VERSION ""

NS_ :

BS_:

BU_: XXX

BO_ 85 CID_JIHOEY: 8 XXX
 SG_ sig_gnukuz : 40|1@1+ (1,0) [0|1] "" XXX
 SG_ sig_xpkfer : 56|8@1+ (1,0) [0|255] "" XXX

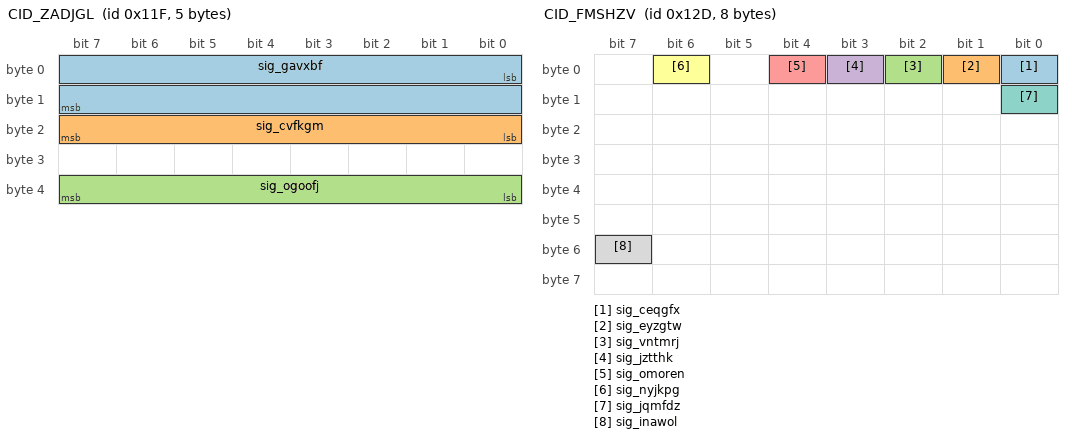
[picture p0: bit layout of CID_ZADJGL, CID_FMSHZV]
BO_ 287 CID_ZADJGL: 5 XXX
 SG_ sig_gavxbf : 0|16@1- (0.1,0) [-450|450] "" XXX
 SG_ sig_cvfkgm : 16|8@1+ (4,0) [0|1020] "" XXX
 SG_ sig_ogoofj : 32|8@1+ (1,0) [0|255] "" XXX

BO_ 289 CID_RFFWJK: 8 XXX
 SG_ sig_duxhzy : 0|12@1+ (1,0) [0|255] "" XXX

BO_ 301 CID_FMSHZV: 8 XXX
 SG_ sig_ceqgfx : 0|1@0+ (1,0) [0|1] "" XXX
 SG_ sig_eyzgtw : 1|1@0+ (1,0) [0|1] "" XXX
 SG_ sig_vntmrj : 2|1@0+ (1,0) [0|1] "" XXX
 SG_ sig_jztthk : 3|1@0+ (1,0) [0|1] "" XXX
 SG_ sig_omoren : 4|1@0+ (1,0) [0|1] "" XXX
 SG_ sig_nyjkpg : 6|1@0+ (1,0) [0|1] "" XXX
 SG_ sig_jqmfdz : 8|1@0+ (1,0) [0|1] "" XXX
 SG_ sig_inawol : 55|1@0+ (1,0) [0|1] "" XXX

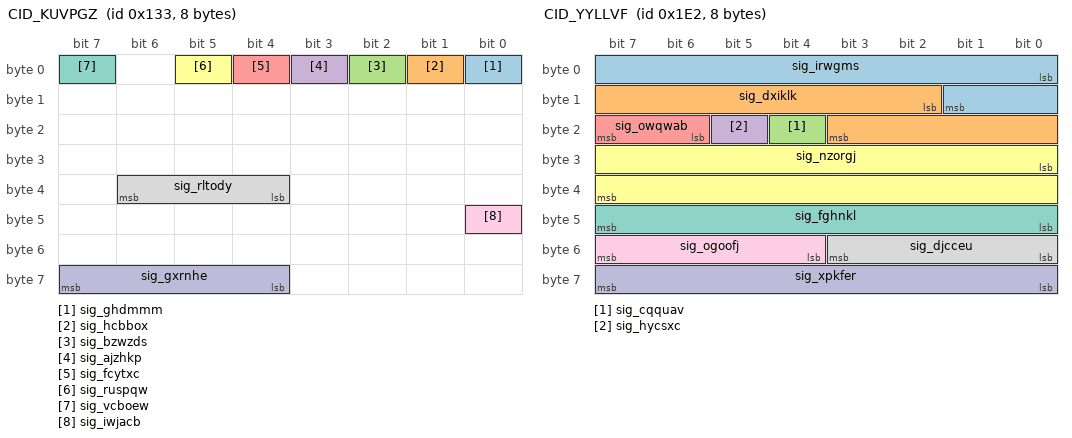
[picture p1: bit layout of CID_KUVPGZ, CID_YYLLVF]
BO_ 307 CID_KUVPGZ: 8 XXX
 SG_ sig_ghdmmm : 0|1@0+ (1,0) [0|1] "" XXX
 SG_ sig_hcbbox : 1|1@1+ (1,0) [0|1] "" XXX
 SG_ sig_bzwzds : 2|1@1+ (1,0) [0|1] "" XXX
 SG_ sig_ajzhkp : 3|1@1+ (1,0) [0|1] "" XXX
 SG_ sig_fcytxc : 4|1@0+ (1,0) [0|1] "" XXX
 SG_ sig_ruspqw : 5|1@0+ (1,0) [0|1] "" XXX
 SG_ sig_vcboew : 7|1@0+ (1,0) [0|1] "" XXX
 SG_ sig_rltody : 36|3@1+ (1,0) [0|7] "" XXX
 SG_ sig_iwjacb : 40|1@0+ (1,0) [0|1] "" XXX
 SG_ sig_gxrnhe : 63|4@0+ (1,0) [0|15] "" XXX

BO_ 482 CID_YYLLVF: 8 XXX
 SG_ sig_irwgms : 0|10@1- (0.01,0) [0|5] "" XXX
 SG_ sig_dxiklk : 10|10@1- (0.01,0) [-5|0] "" XXX
 SG_ sig_cqquav : 20|1@0+ (1,0) [0|1] "" XXX
 SG_ sig_hycsxc : 21|1@0+ (1,0) [0|1] "" XXX
 SG_ sig_owqwab : 22|2@1+ (1,0) [0|1] "" XXX
 SG_ sig_nzorgj : 24|16@1- (0.1,0) [-780|779.9] "" XXX
 SG_ sig_fghnkl : 47|8@0+ (1,0) [0|255] "" XXX
 SG_ sig_djcceu : 48|4@1+ (1,0) [0|15] "" XXX
 SG_ sig_ogoofj : 52|4@1+ (1,0) [0|15] "" XXX
 SG_ sig_xpkfer : 56|8@1+ (1,0) [0|255] "" XXX

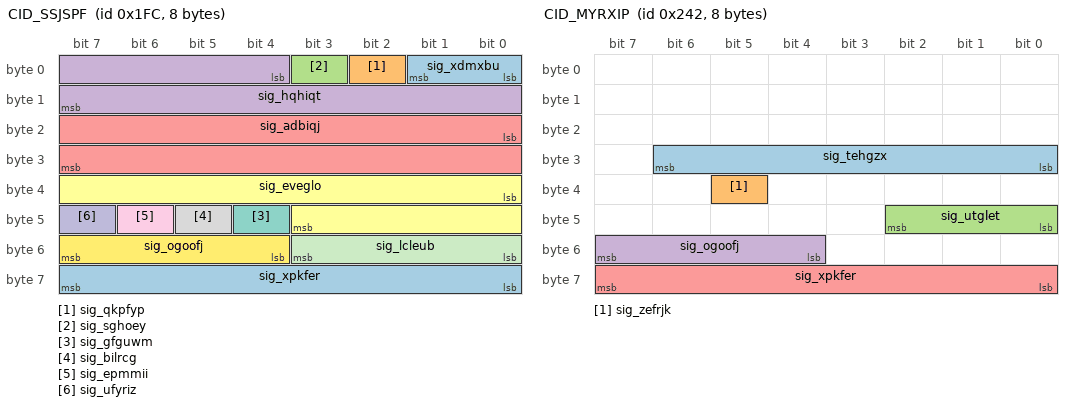
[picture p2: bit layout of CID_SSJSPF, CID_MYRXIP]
BO_ 508 CID_SSJSPF: 8 XXX
 SG_ sig_xdmxbu : 0|2@1+ (1,0) [0|1] "" XXX
 SG_ sig_qkpfyp : 2|1@1+ (1,0) [0|1] "" XXX
 SG_ sig_sghoey : 3|1@0+ (1,0) [0|1] "" XXX
 SG_ sig_hqhiqt : 4|12@1- (1,0) [-2048|2047] "" XXX
 SG_ sig_adbiqj : 16|16@1- (0.1,0) [-780|779.9] "Deg" XXX
 SG_ sig_eveglo : 32|12@1- (1,0) [0|63] "" XXX
 SG_ sig_gfguwm : 44|1@0+ (1,0) [0|1] "" XXX
 SG_ sig_bilrcg : 45|1@1+ (1,0) [0|255] "" XXX
 SG_ sig_epmmii : 46|1@1+ (1,0) [0|1] "" XXX
 SG_ sig_ufyriz : 47|1@0+ (1,0) [0|3] "" XXX
 SG_ sig_lcleub : 48|4@1+ (1,0) [0|15] "" XXX
 SG_ sig_ogoofj : 52|4@1+ (1,0) [0|15] "" XXX
 SG_ sig_xpkfer : 56|8@1+ (1,0) [0|255] "" XXX

BO_ 578 CID_MYRXIP: 8 XXX
 SG_ sig_tehgzx : 30|7@0+ (1,0) [0|127] "" XXX
 SG_ sig_zefrjk : 37|1@0+ (1,0) [0|1] "" XXX
 SG_ sig_utglet : 40|3@1+ (1,0) [0|7] "" XXX
 SG_ sig_ogoofj : 55|4@0+ (1,0) [0|15] "" XXX
 SG_ sig_xpkfer : 56|8@1+ (1,0) [0|255] "" XXX

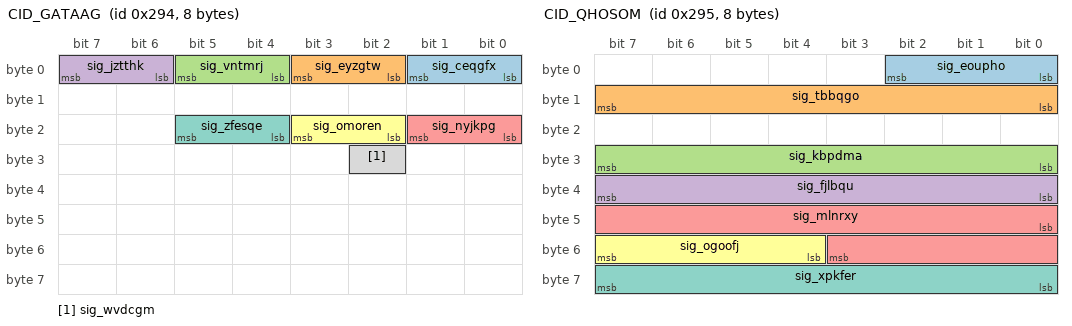
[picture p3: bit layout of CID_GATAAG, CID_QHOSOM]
BO_ 660 CID_GATAAG: 8 XXX
 SG_ sig_ceqgfx : 1|2@0+ (1,0) [0|3] "" XXX
 SG_ sig_eyzgtw : 3|2@0+ (1,0) [0|3] "" XXX
 SG_ sig_vntmrj : 5|2@0+ (1,0) [0|3] "" XXX
 SG_ sig_jztthk : 7|2@0+ (1,0) [0|3] "" XXX
 SG_ sig_nyjkpg : 17|2@0+ (1,0) [0|3] "" XXX
 SG_ sig_omoren : 19|2@0+ (1,0) [0|3] "" XXX
 SG_ sig_zfesqe : 21|2@0+ (1,0) [0|3] "" XXX
 SG_ sig_wvdcgm : 26|1@0+ (1,0) [0|1] "" XXX

BO_ 661 CID_QHOSOM: 8 XXX
 SG_ sig_eoupho : 2|3@0+ (1,0) [0|7] "" XXX
 SG_ sig_tbbqgo : 15|8@0+ (1,0) [0|255] "" XXX
 SG_ sig_kbpdma : 31|8@0+ (1,0) [0|255] "" XXX
 SG_ sig_fjlbqu : 32|8@1+ (1,0) [0|255] "" XXX
 SG_ sig_mlnrxy : 40|12@1+ (1,0) [0|255] "" XXX
 SG_ sig_ogoofj : 52|4@1+ (1,0) [0|15] "" XXX
 SG_ sig_xpkfer : 63|8@0+ (1,0) [0|255] "" XXX

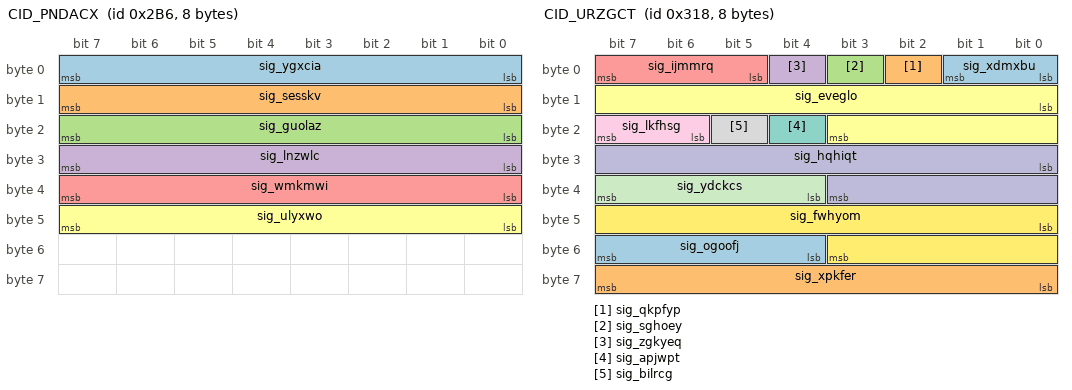
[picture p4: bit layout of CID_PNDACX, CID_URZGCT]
BO_ 694 CID_PNDACX: 8 XXX
 SG_ sig_ygxcia : 7|8@0+ (1,0) [0|255] "" XXX
 SG_ sig_sesskv : 15|8@0+ (1,0) [0|255] "" XXX
 SG_ sig_guolaz : 23|8@0+ (1,0) [0|255] "" XXX
 SG_ sig_lnzwlc : 31|8@0+ (1,0) [0|255] "" XXX
 SG_ sig_wmkmwi : 39|8@0+ (1,0) [0|255] "" XXX
 SG_ sig_ulyxwo : 47|8@0+ (1,0) [0|255] "" XXX

BO_ 790 CID_ICEMTY: 8 XXX
 SG_ sig_aetari : 3|4@0+ (1,0) [0|1] "" XXX
 SG_ sig_behhnb : 4|2@1+ (1,0) [0|3] "" XXX
 SG_ sig_fcgjns : 6|2@1+ (1,0) [0|3] "" XXX
 SG_ sig_ttofsc : 8|2@1+ (1,0) [0|3] "" XXX
 SG_ sig_neyqtc : 10|1@1+ (1,0) [0|1] "" XXX
 SG_ sig_qeffuc : 11|4@1+ (1,0) [0|1] "" XXX
 SG_ sig_ivestz : 15|1@0+ (1,0) [0|1] "" XXX
 SG_ sig_nzorgj : 16|11@1- (1,0) [-1024|1023] "" XXX
 SG_ sig_cqquav : 27|1@1+ (1,0) [0|1] "" XXX
 SG_ sig_hycsxc : 28|1@1+ (1,0) [0|3] "" XXX
 SG_ sig_ygosne : 29|1@0+ (1,0) [0|1] "" XXX
 SG_ sig_qovfsc : 30|1@0+ (1,0) [0|1] "" XXX
 SG_ sig_ddlsdn : 31|1@0+ (1,0) [0|1] "" XXX
 SG_ sig_cqrnwn : 32|2@1+ (1,0) [0|3] "" XXX
 SG_ sig_druepb : 34|2@1+ (1,0) [0|3] "" XXX
 SG_ sig_nrskxj : 36|4@1+ (1,0) [0|3] "" XXX
 SG_ sig_vofyzf : 40|8@1+ (5,-5) [-5|1270] "" XXX
 SG_ sig_anhmit : 49|2@0+ (1,0) [0|3] "" XXX
 SG_ sig_gveedt : 51|2@0+ (1,0) [0|3] "" XXX
 SG_ sig_ogoofj : 52|4@1+ (1,0) [0|15] "" XXX
 SG_ sig_xpkfer : 56|8@1+ (1,0) [0|15] "" XXX

BO_ 792 CID_URZGCT: 8 XXX
 SG_ sig_xdmxbu : 0|2@1+ (1,0) [0|1] "" XXX
 SG_ sig_qkpfyp : 2|1@1+ (1,0) [0|1] "" XXX
 SG_ sig_sghoey : 3|1@1+ (1,0) [0|1] "" XXX
 SG_ sig_zgkyeq : 4|1@1+ (1,0) [0|1] "" XXX
 SG_ sig_ijmmrq : 5|3@1+ (1,0) [0|1] "" XXX
 SG_ sig_eveglo : 8|12@1- (1,0) [-2048|2047] "" XXX
 SG_ sig_apjwpt : 20|1@1+ (1,0) [0|1] "" XXX
 SG_ sig_bilrcg : 21|1@1+ (1,0) [0|1] "" XXX
 SG_ sig_lkfhsg : 22|2@1+ (1,0) [0|15] "" XXX
 SG_ sig_hqhiqt : 24|12@1- (1,0) [-2048|2047] "" XXX
 SG_ sig_ydckcs : 36|4@1+ (1,0) [0|15] "" XXX
 SG_ sig_fwhyom : 40|12@1+ (1,0) [0|4095] "" XXX
 SG_ sig_ogoofj : 52|4@1+ (1,0) [0|15] "" XXX
 SG_ sig_xpkfer : 56|8@1+ (1,0) [0|255] "" XXX

BO_ 813 CID_DNRSZU: 8 XXX
 SG_ sig_tvtsdj : 0|9@1+ (0.5,0) [0|255.5] "" XXX
 SG_ sig_uzxyxi : 9|1@1+ (1,0) [0|1] "" XXX
 SG_ sig_edmiby : 10|3@1+ (1,0) [0|7] "" XXX
 SG_ sig_hxqovv : 13|3@1+ (1,0) [0|7] "" XXX
 SG_ sig_lecqoe : 16|1@1+ (1,0) [0|1] "" XXX
 SG_ sig_ordlki : 17|1@1+ (1,0) [0|1] "" XXX
 SG_ sig_sghoey : 18|1@1+ (1,0) [0|1] "" XXX
 SG_ sig_urarbg : 19|3@1+ (1,0) [0|1] "" XXX
 SG_ sig_fbrvkk : 22|1@0+ (1,0) [0|1] "" XXX
 SG_ sig_cjimsh : 23|1@0+ (1,0) [0|1] "" XXX
 SG_ sig_ttofsc : 24|1@1+ (1,0) [0|1] "" XXX
 SG_ sig_fmpglv : 25|7@1+ (1,0) [0|127] "" XXX
 SG_ sig_kmukoz : 32|4@1+ (1,0) [0|15] "" XXX
 SG_ sig_bcfdrp : 36|12@1+ (1,0) [0|4095] "" XXX
 SG_ sig_ogoofj : 48|4@1+ (1,0) [0|15] "" XXX
 SG_ sig_eovqym : 55|4@0+ (1,0) [0|15] "" XXX
 SG_ sig_xpkfer : 56|8@1+ (1,0) [0|255] "" XXX

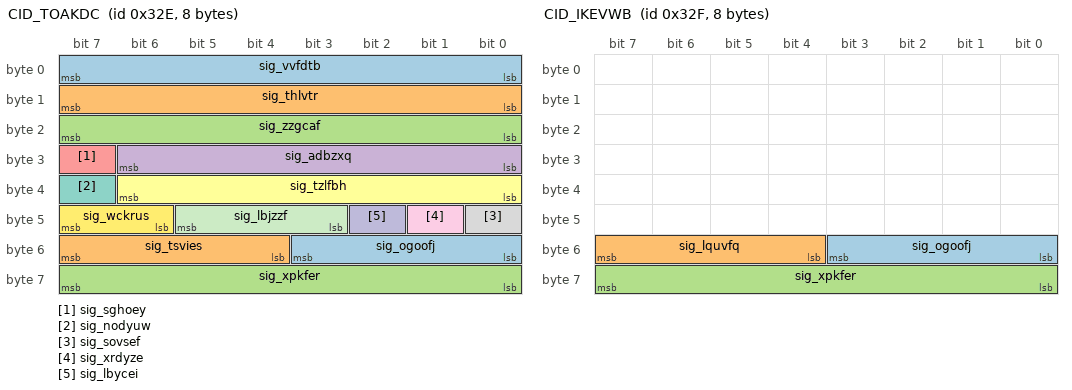
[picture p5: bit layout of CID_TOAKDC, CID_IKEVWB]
BO_ 814 CID_TOAKDC: 8 XXX
 SG_ sig_vvfdtb : 0|8@1+ (0.05,-5) [-100|155] "" XXX
 SG_ sig_thlvtr : 8|8@1+ (0.05,-5) [0|1.26] "" XXX
 SG_ sig_zzgcaf : 16|8@1+ (0.05,-5) [0|1.26] "" XXX
 SG_ sig_adbzxq : 24|7@1+ (0.2,0) [0|12.7] "" XXX
 SG_ sig_sghoey : 31|1@0+ (1,0) [0|1] "" XXX
 SG_ sig_tzlfbh : 32|7@1+ (0.2,-16) [0|12.7] "" XXX
 SG_ sig_nodyuw : 39|1@0+ (1,0) [0|1] "" XXX
 SG_ sig_sovsef : 40|1@0+ (1,0) [0|1] "" XXX
 SG_ sig_xrdyze : 41|1@0+ (1,0) [0|1] "" XXX
 SG_ sig_lbycei : 42|1@1+ (1,0) [0|3] "" XXX
 SG_ sig_lbjzzf : 45|3@0+ (1,0) [0|1] "" XXX
 SG_ sig_wckrus : 46|2@1+ (1,0) [0|3] "" XXX
 SG_ sig_ogoofj : 48|4@1+ (1,0) [0|15] "" XXX
 SG_ sig_tsvies : 55|4@0+ (1,0) [0|15] "" XXX
 SG_ sig_xpkfer : 56|8@1+ (1,0) [0|255] "" XXX

BO_ 815 CID_IKEVWB: 8 XXX
 SG_ sig_ogoofj : 48|4@1+ (1,0) [0|15] "" XXX
 SG_ sig_lquvfq : 55|4@0+ (1,0) [0|15] "" XXX
 SG_ sig_xpkfer : 56|8@1+ (1,0) [0|255] "" XXX

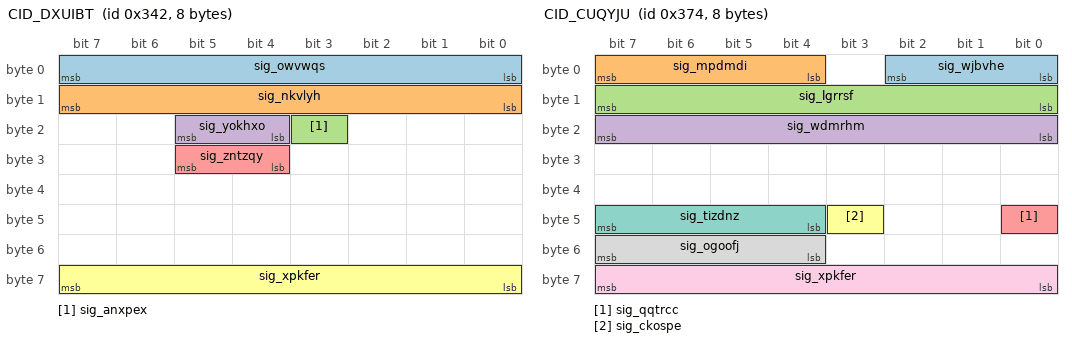
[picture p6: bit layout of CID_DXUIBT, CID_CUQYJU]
BO_ 834 CID_DXUIBT: 8 XXX
 SG_ sig_owvwqs : 0|8@1+ (0.01,0) [0|2.55] "" XXX
 SG_ sig_nkvlyh : 8|8@1+ (0.01,0) [0|2.55] "" XXX
 SG_ sig_anxpex : 19|1@1+ (1,0) [0|1] "" XXX
 SG_ sig_yokhxo : 20|2@1+ (1,0) [0|255] "" XXX
 SG_ sig_zntzqy : 28|2@1+ (1,0) [0|1] "" XXX
 SG_ sig_xpkfer : 56|8@1+ (1,0) [0|255] "" XXX

BO_ 884 CID_CUQYJU: 8 MRR
 SG_ sig_wjbvhe : 2|3@0+ (1,0) [0|3] "" MRR
 SG_ sig_mpdmdi : 7|4@0+ (1,0) [0|15] "" MRR
 SG_ sig_lgrrsf : 15|8@0+ (0.1,-12) [0|255] "" MRR
 SG_ sig_wdmrhm : 23|8@0+ (1,-100) [0|255] "" MRR
 SG_ sig_qqtrcc : 40|1@0+ (1,0) [0|3] "" MRR
 SG_ sig_ckospe : 43|1@0+ (1,0) [0|1] "" XXX
 SG_ sig_tizdnz : 44|4@1+ (1,0) [0|15] "" XXX
 SG_ sig_ogoofj : 52|4@1+ (1,0) [0|15] "" MRR
 SG_ sig_xpkfer : 56|8@1+ (1,0) [0|255] "" MRR

BO_ 944 CID_RWHYUQ: 8 XXX
 SG_ sig_dmeosj : 1|2@0+ (1,0) [0|3] "" XXX
 SG_ sig_choecz : 2|1@0+ (1,0) [0|1] "" XXX
 SG_ sig_popogx : 4|2@0+ (1,0) [0|3] "" XXX
 SG_ sig_dvoegn : 5|1@0+ (1,0) [0|1] "" XXX
 SG_ sig_jycthk : 6|1@0+ (1,0) [0|1] "" XXX
 SG_ sig_bxyvql : 7|1@0+ (1,0) [0|1] "" XXX
 SG_ sig_kcycbv : 8|1@0+ (1,0) [0|1] "" XXX
 SG_ sig_axuhtk : 11|3@0+ (1,0) [0|7] "" XXX
 SG_ sig_jhoeds : 12|1@0+ (1,0) [0|1] "" XXX
 SG_ sig_wzkwbj : 14|2@0+ (1,0) [0|3] "" XXX
 SG_ sig_yomjtv : 15|1@0+ (1,0) [0|1] "" XXX
 SG_ sig_hzegkd : 16|1@0+ (1,0) [0|1] "" XXX
 SG_ sig_nadtzy : 18|2@0+ (1,0) [0|3] "" XXX
 SG_ sig_dlfzkr : 19|1@0+ (1,0) [0|1] "" XXX
 SG_ sig_dobmjw : 23|4@0+ (1,0) [0|15] "" XXX
 SG_ sig_ngcrsp : 24|28@1+ (1,0) [0|268435455] "" XXX
 SG_ sig_ogoofj : 52|4@1+ (1,0) [0|15] "" XXX
 SG_ sig_xpkfer : 56|8@1+ (1,0) [0|255] "" XXX

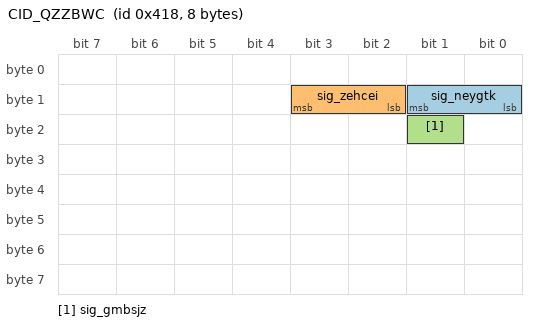
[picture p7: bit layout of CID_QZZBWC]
BO_ 1048 CID_QZZBWC: 8 XXX
 SG_ sig_neygtk : 9|2@0+ (1,0) [0|1] "" XXX
 SG_ sig_zehcei : 11|2@0+ (1,0) [0|1] "" XXX
 SG_ sig_gmbsjz : 17|1@0+ (1,0) [0|1] "" XXX

VAL_ 578 sig_utglet 4 "D" 2 "R" 3 "N" 1 "P";
VAL_ 790 sig_aetari 11 "AutoFullBeamActive" 2 "AutoFullBeamInactive";
VAL_ 790 sig_behhnb 0 "GRAY" 1 "GREEN" 2 "YELLOW" 3 "RED";
VAL_ 790 sig_fcgjns 3 "ALARM_AND_LKA" 2 "LKA" 1 "ALARM" 0 "DISABLE";
VAL_ 790 sig_druepb 0 "GRAY" 1 "GREEN" 2 "YELLOW" 3 "RED";
VAL_ 790 sig_anhmit 0 "VIBRATION" 1 "AUDIO" 2 "AUDIO_AND_VIBRATION";
VAL_ 792 sig_xdmxbu 0 "NotReady" 1 "Ready" 2 "Active" 3 "TemporaryFail";
VAL_ 813 sig_edmiby 4 "4BAR" 3 "3BAR" 2 "2BAR" 1 "1BAR";
VAL_ 813 sig_urarbg 0 "OFF" 2 "ACC_ON" 3 "ACC_ACTIVE" 5 "FORCE_ACCEL" 7 "ERROR";
VAL_ 813 sig_fmpglv 36 "ACC_ERROR" 22 "OVERRIDE" 12 "ENGAGE" 8 "DISENGAGE" 20 "ACC_ON" 32 "ACC_OFF" 48 "CHECK_GEAR_D" 16 "FORCE_ACCEL" 0 "NONE";
VAL_ 814 sig_lbjzzf 0 "Off" 1 "Passive" 2 "StandBy" 3 "ActiveControl" 4 "BrakeOnly" 5 "Override" 6 "Standstill" 7 "Failure";
VAL_ 814 sig_wckrus 0 "Softoff" 1 "Fastoff" 2 "Immediateoff" 3 "Initial";
VAL_ 834 sig_yokhxo 2 "SPORT" 1 "ECO" 0 "SNOW";
VAL_ 834 sig_zntzqy 3 "HEV" 2 "FORCE_EV" 1 "EV";
VAL_ 944 sig_popogx 0 "NOTPRESSED" 1 "DOWN_SETSPEED" 3 "UP_RESETSPEED";
